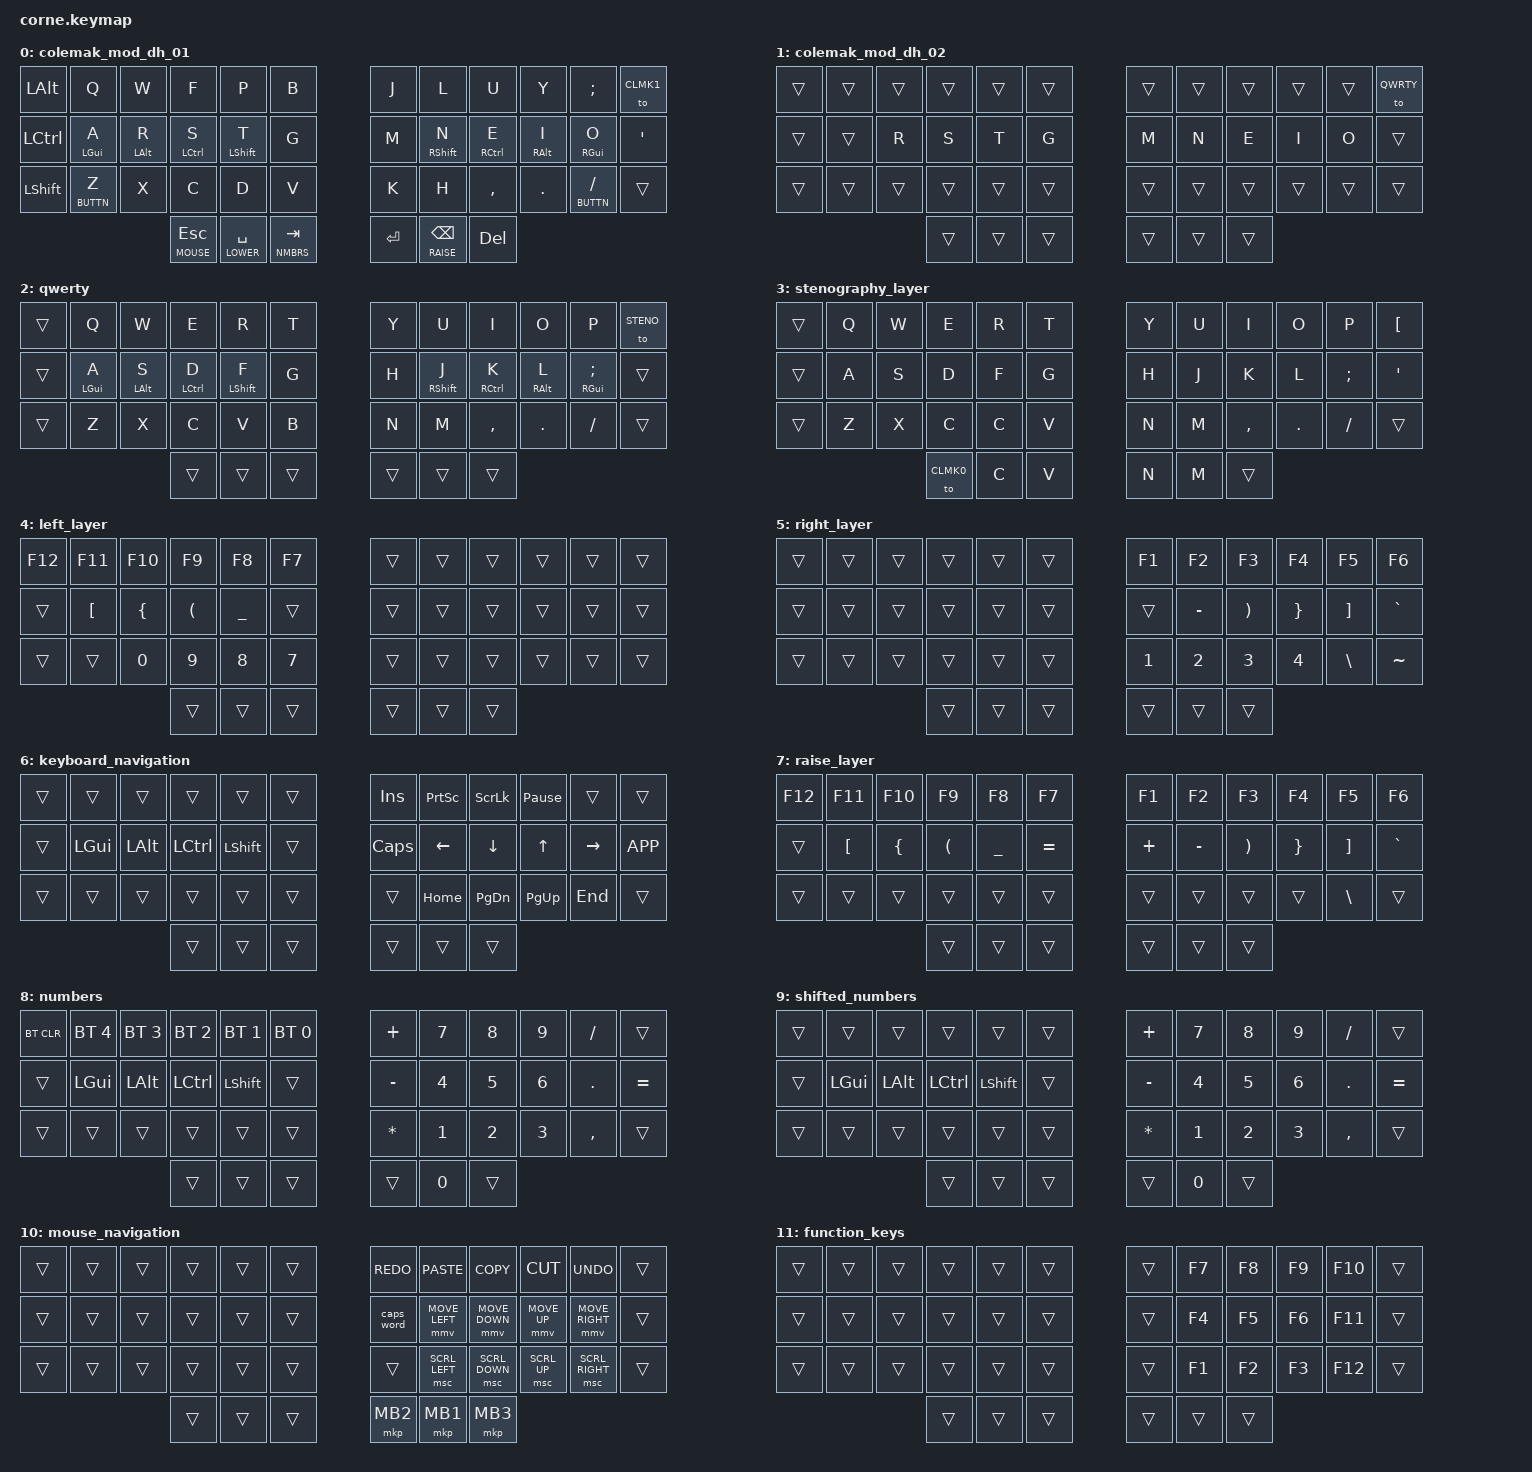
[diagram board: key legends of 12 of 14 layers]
// * Corne Keymap Config

#include <behaviors.dtsi>
#include <dt-bindings/zmk/keys.h>
#include <dt-bindings/zmk/bt.h>

#define CLMK0 0
#define CLMK1 1
#define QWRTY 2
#define STENO 3
#define LEFTL 4
#define RGHTL 5
#define LOWER 6
#define RAISE 7
#define NMBRS 8
#define NMBR1 9
#define MOUSE 10
#define FKEYS 11
#define BUTTN 12
#define BLANK 99

#define ZMK_POINTING_DEFAULT_MOVE_VAL 1500  // default: 600
#define ZMK_POINTING_DEFAULT_SCRL_VAL 20    // default: 10

#include <dt-bindings/zmk/pointing.h>

&mt {                           // Mod Tap
  tapping-term-ms = <250>;
};

&lt {                           // Layer Tap
  tapping-term-ms = <250>;
};

&sl {                           // Sticky Layer 
  release-after-ms = <2000>;
};

&sk {                           // Sticky Key
  release-after-ms = <2000>;
  // quick-release;
  // /delete-property/ ignore-modifiers;
};

/ {
  behaviors {
  hm: homerow_mods {
      compatible            = "zmk,behavior-hold-tap";
      #binding-cells        = <2>;
      tapping-term-ms       = <250>;
      quick-tap-ms          = <0>;
      flavor                = "tap-preferred";
      bindings              = <&kp>, <&kp>;
    };

  bhm: balanced_homerow_mods {
      compatible            = "zmk,behavior-hold-tap";
      #binding-cells        = <2>;
      tapping-term-ms       = <250>;
      quick-tap-ms          = <0>;
      flavor                = "balanced";
      bindings              = <&kp>, <&kp>;
    };

  rpi: require_prior_idle {
      compatible            = "zmk,behavior-hold-tap";
      #binding-cells        = <2>;
      flavor                = "tap-preferred";
      tapping-term-ms       = <250>;
      quick-tap-ms          = <250>;
      require-prior-idle-ms = <125>;
      bindings              = <&kp>, <&kp>;
    };
  };


// ** Combos

  // -------------------------------------     -------------------------------------
  // |   0 |   1 |   2 |   3 |   4 |   5 |     |   6 |   7 |   8 |   9 |  10 |  11 |
  // |  12 |  13 |  14 |  15 |  16 |  17 |     |  18 |  19 |  20 |  21 |  22 |  23 |
  // |  24 |  25 |  26 |  27 |  28 |  29 |     |  30 |  31 |  32 |  33 |  34 |  35 |
  // -------------------------------------     -------------------------------------
  //                   |  36 |  37 |  38 |     |  39 |  40 |  41 |
  //                   -------------------     -------------------

  combos {
    compatible = "zmk,combos";

    combo_goto_shifted_navigation {
      timeout-ms    = <50>;
      key-positions = <16 37>;
      bindings      = <&mo MOUSE>;
      slow-release;
    };

    // combo_goto_shifted_numbers {
    //   timeout-ms    = <50>;
    //   key-positions = <16 38>;
    //   bindings      = <&mo NMBR1>;
    //   // slow-release;
    // };

    // combo_left_shift {
    //   timeout-ms    = <50>;
    //   key-positions = <15 16>;
    //   bindings      = <&kp LSHIFT>;
    //   // slow-release;
    // };

    // combo_right_shift {
    //   timeout-ms    = <50>;
    //   key-positions = <19 20>;
    //   bindings      = <&kp RSHIFT>;
    //   // slow-release;
    // };

    // combo_esc {
    //   timeout-ms    = <50>;
    //   key-positions = <0 1>;
    //   bindings      = <&kp ESC>;
    // };

    // combo_left {
    //   timeout-ms    = <50>;
    //   key-positions = <7 8>;
    //   bindings      = <&mo LEFTL>;
    // };

    // combo_right {
    //   timeout-ms    = <50>;
    //   key-positions = <3 4>;
    //   bindings      = <&mo RGHTL>;
    // };

    // combo_left_shift {
    //   timeout-ms    = <50>;
    //   key-positions = <16 37>;
    //   bindings      = <&kp LSHIFT>;
    //   slow-release;
    // };

    // combo_left_ctrl {
    //   timeout-ms    = <50>;
    //   key-positions = <15 37>;
    //   bindings      = <&kp LCTRL>;
    //   slow-release;
    // };

    // combo_left_alt {
    //   timeout-ms    = <50>;
    //   key-positions = <14 37>;
    //   bindings      = <&kp LALT>;
    //   slow-release;
    // };

    // combo_left_gui {
    //   timeout-ms    = <50>;
    //   key-positions = <13 37>;
    //   bindings      = <&kp LGUI>;
    //   slow-release;
    // };

    // combo_right_shift {
    //   timeout-ms    = <50>;
    //   key-positions = <19 40>;
    //   bindings      = <&kp RSHIFT>;
    //   slow-release;
    // };

    // combo_right_ctrl {
    //   timeout-ms    = <50>;
    //   key-positions = <18 40>;
    //   bindings      = <&kp RCTRL>;
    //   slow-release;
    // };

    // combo_right_alt {
    //   timeout-ms    = <50>;
    //   key-positions = <17 40>;
    //   bindings      = <&kp RALT>;
    //   slow-release;
    // };

    // combo_right_gui {
    //   timeout-ms    = <50>;
    //   key-positions = <16 40>;
    //   bindings      = <&kp RGUI>;
    //   slow-release;
    // };

  };

  keymap {
    compatible = "zmk,keymap";

// ** Colemak Mod DH (with homerow mods)

colemak_mod_dh_01 {
  // Colemak-mod-DH Keyboard Layout (with homerow mods)
  // -------------------------------------     -------------------------------------
  // | ALT |  Q  |  W  |  F  |  P  |  B  |     |  J  |  L  |  U  |  Y  |  ;  |CMLK1|
  // | CTRL|  A  |  R  |  S  |  T  |  G  |     |  M  |  N  |  E  |  I  |  O  |  '  |
  // |SHIFT|  Z  |  X  |  C  |  D  |  V  |     |  K  |  H  |  ,  |  .  |  /  |     |
  // -------------------------------------     -------------------------------------
  //                   | ESC | SPC | TAB |     | RET | BSPC| DEL |
  //                   -------------------     -------------------
  bindings = <
    &kp   LALT &kp       Q &kp      W &kp       F &kp        P &kp B     &kp J &kp        L &kp       U &kp      Y &kp   SEMI     &to CLMK1
    &kp  LCTRL &hm LGUI  A &hm LALT R &hm LCTRL S &hm LSHIFT T &kp G     &kp M &hm RSHIFT N &hm RCTRL E &hm RALT I &hm RGUI O     &kp SQT
    &kp LSHIFT &lt BUTTN Z &kp      X &kp       C &kp        D &kp V     &kp K &kp        H &kp   COMMA &kp    DOT &lt BUTTN FSLH &trans
                         &lt MOUSE ESC &lt LOWER SPACE &lt NMBRS TAB     &kp RET &lt RAISE BSPC &kp DEL
    >;
};

// ** Colemak Mod DH (without homerow mods)

colemak_mod_dh_02 {
  // Colemak-mod-DH Keyboard Layout (without homerow mods)
  // -------------------------------------     -------------------------------------
  // |     |     |     |     |     |     |     |     |     |     |     |     |QWRTY|
  // |     |     |  R  |  S  |  T  |  G  |     |  M  |  N  |  E  |  I  |     |     |
  // |     |     |     |     |     |     |     |     |     |     |     |     |     |
  // -------------------------------------     -------------------------------------
  //                   |     |     |     |     |     |     |     |
  //                   -------------------     -------------------
  bindings = <
    &trans &trans &trans &trans &trans &trans     &trans &trans &trans &trans &trans &to QWRTY
    &trans &trans &kp R  &kp S  &kp T  &kp G      &kp M  &kp N  &kp E  &kp I  &kp O  &trans
    &trans &trans &trans &trans &trans &trans     &trans &trans &trans &trans &trans &trans
                         &trans &trans &trans     &trans &trans &trans
    >;
};

// ** Qwerty Layer

qwerty {
  // QWERTY Keybord Layout
  // -------------------------------------     -------------------------------------
  // |     |  Q  |  W  |  E  |  R  |  T  |     |  Y  |  U  |  I  |  O  |  P  |STENO|
  // |     |  A  |  S  |  D  |  F  |  G  |     |  H  |  J  |  K  |  L  |  ;  |     |
  // |     |  Z  |  X  |  C  |  V  |  B  |     |  N  |  M  |  ,  |  .  |  /  |     |
  // -------------------------------------     -------------------------------------
  //                   |     |     |     |     |     |     |     |
  //                   -------------------     -------------------
  bindings = <
    &trans &kp      Q &kp      W &kp       E &kp        R &kp T     &kp Y &kp     U    &kp       I &kp      O &kp         P &to STENO
    &trans &hm LGUI A &hm LALT S &hm LCTRL D &hm LSHIFT F &kp G     &kp H &hm RSHIFT J &hm RCTRL K &hm RALT L &hm RGUI SEMI &trans
    &trans &kp      Z &kp      X &kp       C &kp        V &kp B     &kp N &kp        M &kp   COMMA &kp    DOT &kp      FSLH &trans
                                           &trans &trans &trans     &trans &trans &trans
    >;
};

// ** Stenography Layer

stenography_layer {
  // Stenography Keybord Layout
  // -------------------------------------     -------------------------------------
  // |     |  Q  |  W  |  E  |  R  |  T  |     |  Y  |  U  |  I  |  O  |  P  |  [  |
  // |     |  A  |  S  |  D  |  F  |  G  |     |  H  |  J  |  K  |  L  |  ;  |  '  |
  // |     |  Z  |  X  |  C  |  C  |  V  |     |  N  |  M  |  ,  |  .  |  /  |     |
  // -------------------------------------     -------------------------------------
  //                   |CLMK0|  C  |  V  |     |  N  |  M  |     |
  //                   -------------------     -------------------
  bindings = <
    &trans &kp Q &kp W &kp E &kp R &kp T     &kp Y &kp U &kp     I &kp   O &kp    P &kp LBKT
    &trans &kp A &kp S &kp D &kp F &kp G     &kp H &kp J &kp     K &kp   L &kp SEMI &kp SQT
    &trans &kp Z &kp X &kp C &kp C &kp V     &kp N &kp M &kp COMMA &kp DOT &kp FSLH &trans
                   &to CLMK0 &kp C &kp V     &kp N &kp M &trans
    >;
};

// ** Left Layer

left_layer {
  // -------------------------------------     -------------------------------------
  // | F12 | F11 | F10 | F9  | F8  | F7  |     |     |     |     |     |     |     |
  // |     |  [  |  {  |  (  |  _  |     |     |     |     |     |     |     |     |
  // |     |     |  0  |  9  |  8  |  7  |     |     |     |     |     |     |     |
  // -------------------------------------     -------------------------------------
  //                   |     |     |     |     |     |     |     |
  //                   -------------------     -------------------
  bindings = <
    &kp F12 &kp F11  &kp F10  &kp F9   &kp F8    &kp F7     &trans &trans &trans &trans &trans &trans
    &trans  &kp LBKT &kp LBRC &kp LPAR &kp UNDER &trans     &trans &trans &trans &trans &trans &trans
    &trans  &trans   &kp N0   &kp N9   &kp N8    &kp N7     &trans &trans &trans &trans &trans &trans
                                   &trans &trans &trans     &trans &trans &trans
    >;
};

// ** Right Layer

right_layer {
  // -------------------------------------     -------------------------------------
  // |     |     |     |     |     |     |     |  F1 |  F2 | F3  | F4  | F5  |  F6 |
  // |     |     |     |     |     |     |     |     |  -  |  )  |  }  |  ]  |  `  |
  // |     |     |     |     |     |     |     |  1  |  2  |  3  |  4  |  \  |  ~  |
  // -------------------------------------     -------------------------------------
  //                   |     |     |     |     |     |     |     |
  //                   -------------------     -------------------
  bindings = <
    &trans &trans &trans &trans &trans &trans     &kp F1 &kp F2    &kp F3   &kp F4   &kp F5   &kp F6
    &trans &trans &trans &trans &trans &trans     &trans &kp MINUS &kp RPAR &kp RBRC &kp RBKT &kp GRAVE
    &trans &trans &trans &trans &trans &trans     &kp N1 &kp N2    &kp N3   &kp N4   &kp BSLH &kp TILDE
                         &trans &trans &trans     &trans &trans &trans
    >;
};

// ** Keyboard Navigation

keyboard_navigation {
  // -------------------------------------     -------------------------------------
  // |     |     |     |     |     |     |     | INS |PSCRN| SLCK|PAUSE|     |     |
  // |     | GUI | ALT | CTRL|SHIFT|     |     | CAPS| LEFT| DOWN|  UP |RIGHT|K_APP|
  // |     |     |     |     |     |     |     |     | HOME|PG_DN|PG_UP| END |     |
  // -------------------------------------     -------------------------------------
  //                   |     |     |     |     |     |     |     |
  //                   -------------------     -------------------
  bindings = <
    &trans &trans   &trans   &trans    &trans     &trans     &kp INSERT &kp PSCRN &kp  SLCK &kp PAUSE_BREAK &trans    &trans
    &trans &kp LGUI &kp LALT &kp LCTRL &kp LSHIFT &trans     &kp   CAPS &kp  LEFT &kp  DOWN &kp         UP  &kp RIGHT &kp K_APP
    &trans &trans   &trans   &trans    &trans     &trans     &trans     &kp  HOME &kp PG_DN &kp      PG_UP  &kp   END &trans
                                    &trans &trans &trans     &trans &trans &trans
    >;
};

// ** Raise Layer

raise_layer {
  // -------------------------------------     -------------------------------------
  // | F12 | F11 | F10 | F9  | F8  | F7  |     |  F1 |  F2 | F3  | F4  | F5  |  F6 |
  // |     |  [  |  {  |  (  |  _  |  =  |     |  +  |  -  |  )  |  }  |  ]  |  `  |
  // |     |     |     |     |     |     |     |     |     |     |     |  \  |     |
  // -------------------------------------     -------------------------------------
  //                   |     |     |     |     |     |     |     |
  //                   -------------------     -------------------
  bindings = <
    &kp F12 &kp  F11 &kp  F10 &kp   F9 &kp    F8 &kp    F7     &kp   F1 &kp    F2 &kp   F3 &kp   F4 &kp   F5 &kp    F6   
    &trans  &kp LBKT &kp LBRC &kp LPAR &kp UNDER &kp EQUAL     &kp PLUS &kp MINUS &kp RPAR &kp RBRC &kp RBKT &kp GRAVE
    &trans  &trans   &trans   &trans   &trans    &trans        &trans   &trans    &trans   &trans   &kp BSLH &trans
                                   &trans &trans &trans        &trans &trans &trans
    >;
};

// ** Numbers Layer

numbers {
  // -------------------------------------     -------------------------------------
  // |BTCLR| BT5 | BT4 | BT3 | BT2 | BT1 |     |  +  |  7  |  8  |  9  |  /  |     |
  // |     | GUI | ALT | CTRL|SHIFT|     |     |  -  |  4  |  5  |  6  |  .  |  =  |
  // |     |     |     |     |     |     |     |  *  |  1  |  2  |  3  |  ,  |     |
  // -------------------------------------     -------------------------------------
  //                   |     |     |     |     |     |  0  |     |
  //                   -------------------     -------------------
  bindings = <
    &bt BT_CLR &bt BT_SEL 4 &bt BT_SEL 3 &bt BT_SEL 2 &bt BT_SEL 1 &bt BT_SEL 0     &kp PLUS  &kp N7 &kp N8 &kp N9 &kp SLASH &trans
    &trans     &kp LGUI     &kp LALT     &kp LCTRL    &kp LSHIFT   &trans           &kp MINUS &kp N4 &kp N5 &kp N6 &kp DOT   &kp EQUAL
    &trans     &trans       &trans       &trans       &trans       &trans           &kp STAR  &kp N1 &kp N2 &kp N3 &kp COMMA &trans
                                                     &trans &trans &trans           &trans &kp N0 &trans
    >;
};

// ** Shifted Numbers

shifted_numbers {
  // -------------------------------------     -------------------------------------
  // |     |     |     |     |     |     |     |  +  |  &  |  *  |  (  |     |     |
  // |     | GUI | ALT | CTRL|SHIFT|     |     |  -  |  $  |  %  |  ^  |     |     |
  // |     |     |     |     |     |     |     |  *  |  !  |  @  |  #  |     |     |
  // -------------------------------------     -------------------------------------
  //                   |     |     |     |     |     |  )  |     |
  //                   -------------------     -------------------
  bindings = <
    &trans &trans   &trans   &trans    &trans     &trans     &kp PLUS  &kp N7 &kp N8 &kp N9 &kp SLASH &trans
    &trans &kp LGUI &kp LALT &kp LCTRL &kp LSHIFT &trans     &kp MINUS &kp N4 &kp N5 &kp N6 &kp DOT   &kp EQUAL
    &trans &trans   &trans   &trans    &trans     &trans     &kp STAR  &kp N1 &kp N2 &kp N3 &kp COMMA &trans
                                    &trans &trans &trans     &trans &kp N0 &trans
    >;
};

// ** Mouse Navigation

mouse_navigation {
  // -------------------------------------     -------------------------------------
  // |     |     |     |     |     |     |     |     |     |     |     |     |     |
  // |     |     |     |     |     |     |     |     |     |     |     |     |     |
  // |     |     |     |     |     |     |     |     |     |     |     |     |     |
  // -------------------------------------     -------------------------------------
  //                   |     |     |     |     |     |     |     |
  //                   -------------------     -------------------
  bindings = <
    &trans &trans &trans &trans &trans &trans     &kp K_REDO &kp    K_PASTE &kp     K_COPY &kp    K_CUT &kp      K_UNDO &trans
    &trans &trans &trans &trans &trans &trans     &caps_word &mmv MOVE_LEFT &mmv MOVE_DOWN &mmv MOVE_UP &mmv MOVE_RIGHT &trans
    &trans &trans &trans &trans &trans &trans     &trans     &msc SCRL_LEFT &msc SCRL_DOWN &msc SCRL_UP &msc SCRL_RIGHT &trans
                         &trans &trans &trans     &mkp MB2 &mkp MB1 &mkp MB3
    >;
};

// ** Function Keys

function_keys {
  // -------------------------------------     -------------------------------------
  // |     |     |     |     |     |     |     |     |  F7 |  F8 |  F9 | F10 |     |
  // |     |     |     |     |     |     |     |     |  F4 |  F5 |  F6 | F11 |     |
  // |     |     |     |     |     |     |     |     |  F1 |  F2 |  F3 | F12 |     |
  // -------------------------------------     -------------------------------------
  //                   |     |     |     |     |     |     |     |
  //                   -------------------     -------------------
  bindings = <
    &trans &trans &trans &trans &trans &trans     &trans &kp F7 &kp F8 &kp F9 &kp F10 &trans
    &trans &trans &trans &trans &trans &trans     &trans &kp F4 &kp F5 &kp F6 &kp F11 &trans
    &trans &trans &trans &trans &trans &trans     &trans &kp F1 &kp F2 &kp F3 &kp F12 &trans
                         &trans &trans &trans     &trans &trans &trans
    >;
};

// ** Button Layer

button_layer {
  // -------------------------------------     -------------------------------------
  // |     |     |     |     |     |     |     |     |     |     |     |     |     |
  // |     |     |     |     |     |     |     |     |     |     |     |     |     |
  // |     |     |     |     |     |     |     |     |     |     |     |     |     |
  // -------------------------------------     -------------------------------------
  //                   |     |     |     |     |     |     |     |
  //                   -------------------     -------------------
  bindings = <
    &trans &kp K_UNDO &kp K_CUT &kp K_COPY &kp K_PASTE &kp K_REDO     &kp K_REDO &kp K_PASTE &kp K_COPY &kp K_CUT &kp K_UNDO &trans
    &trans &kp   LGUI &kp  LALT &kp  LCTRL &kp  LSHIFT &trans         &trans     &kp  RSHIFT &kp  RCTRL &kp  RALT &kp   RGUI &trans
    &trans &kp K_UNDO &kp K_CUT &kp K_COPY &kp K_PASTE &kp K_REDO     &kp K_REDO &kp K_PASTE &kp K_COPY &kp K_CUT &kp K_UNDO &trans
                                &mkp   MB3 &mkp    MB1 &mkp   MB2     &mkp   MB2 &mkp    MB1 &mkp   MB3
    >;
};

// ** Blank Layer

blank_layer {
  // -------------------------------------     -------------------------------------
  // |     |     |     |     |     |     |     |     |     |     |     |     |     |
  // |     |     |     |     |     |     |     |     |     |     |     |     |     |
  // |     |     |     |     |     |     |     |     |     |     |     |     |     |
  // -------------------------------------     -------------------------------------
  //                   |     |     |     |     |     |     |     |
  //                   -------------------     -------------------
  bindings = <
    &trans &trans &trans &trans &trans &trans     &trans &trans &trans &trans &trans &trans
    &trans &trans &trans &trans &trans &trans     &trans &trans &trans &trans &trans &trans
    &trans &trans &trans &trans &trans &trans     &trans &trans &trans &trans &trans &trans
                         &trans &trans &trans     &trans &trans &trans
    >;
};

};
};
